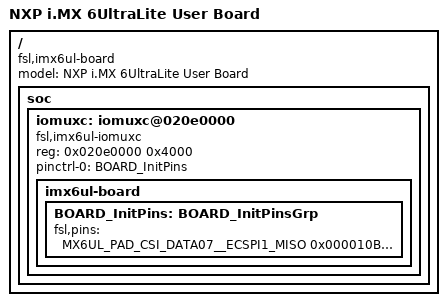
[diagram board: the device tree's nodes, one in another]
/***********************************************************************************************************************
 * This file was generated by the MCUXpresso Config Tools. Any manual edits made to this file
 * will be overwritten if the respective MCUXpresso Config Tools is used to update this file.
 **********************************************************************************************************************/

/*
 * TEXT BELOW IS USED AS SETTING FOR TOOLS *************************************
!!GlobalInfo
product: Pins v11.0
processor: MCIMX6G2xxx05
package_id: MCIMX6G2CVM05
mcu_data: i_mx_2_0
processor_version: 11.0.0
 * BE CAREFUL MODIFYING THIS COMMENT - IT IS YAML SETTINGS FOR TOOLS ***********
 */

/*
 * TEXT BELOW IS USED AS SETTING FOR TOOLS *************************************
BOARD_InitPins:
- options: {callFromInitBoot: 'false', coreID: ca7}
- pin_list:
  - {pin_num: A14, peripheral: ECSPI1, signal: ecspi_mosi, pin_signal: LCD_DATA22}
  - {pin_num: C14, peripheral: ECSPI1, signal: ecspi_sclk, pin_signal: LCD_DATA20}
  - {pin_num: B14, peripheral: ECSPI1, signal: 'ecspi_ss, 0', pin_signal: LCD_DATA21}
  - {pin_num: D14, peripheral: GPIO3, signal: 'gpio_io, 24', pin_signal: LCD_DATA19}
  - {pin_num: D1, peripheral: ECSPI1, signal: ecspi_miso, pin_signal: CSI_DATA07}
  - {pin_num: B13, peripheral: GPIO3, signal: 'gpio_io, 22', pin_signal: LCD_DATA17}
 * BE CAREFUL MODIFYING THIS COMMENT - IT IS YAML SETTINGS FOR TOOLS ***********
 */

/dts-v1/;

#include "skeleton.dtsi"
#include "imx6ul-pinfunc.h"

/ {
    model = "NXP i.MX 6UltraLite User Board";
    compatible = "fsl,imx6ul-board", "fsl,imx6ul";

    soc {
        #address-cells = <1>;
        #size-cells = <1>;

        iomuxc: iomuxc@020e0000 {
            compatible = "fsl,imx6ul-iomuxc";
            reg = <0x020e0000 0x4000>;
        };
    };
};

&iomuxc {
    pinctrl-names = "default";
    pinctrl-0 = <&BOARD_InitPins>;
    imx6ul-board {
        BOARD_InitPins: BOARD_InitPinsGrp {                /*!< Function assigned for the core: Cortex-A7[ca7] */
            fsl,pins = <
                MX6UL_PAD_CSI_DATA07__ECSPI1_MISO          0x000010B0
                MX6UL_PAD_LCD_DATA17__GPIO3_IO22           0x000010B0
                MX6UL_PAD_LCD_DATA19__GPIO3_IO24           0x000010B0
                MX6UL_PAD_LCD_DATA20__ECSPI1_SCLK          0x000010B0
                MX6UL_PAD_LCD_DATA21__ECSPI1_SS0           0x000010B0
                MX6UL_PAD_LCD_DATA22__ECSPI1_MOSI          0x000010B0
            >;
        };
    };
};

